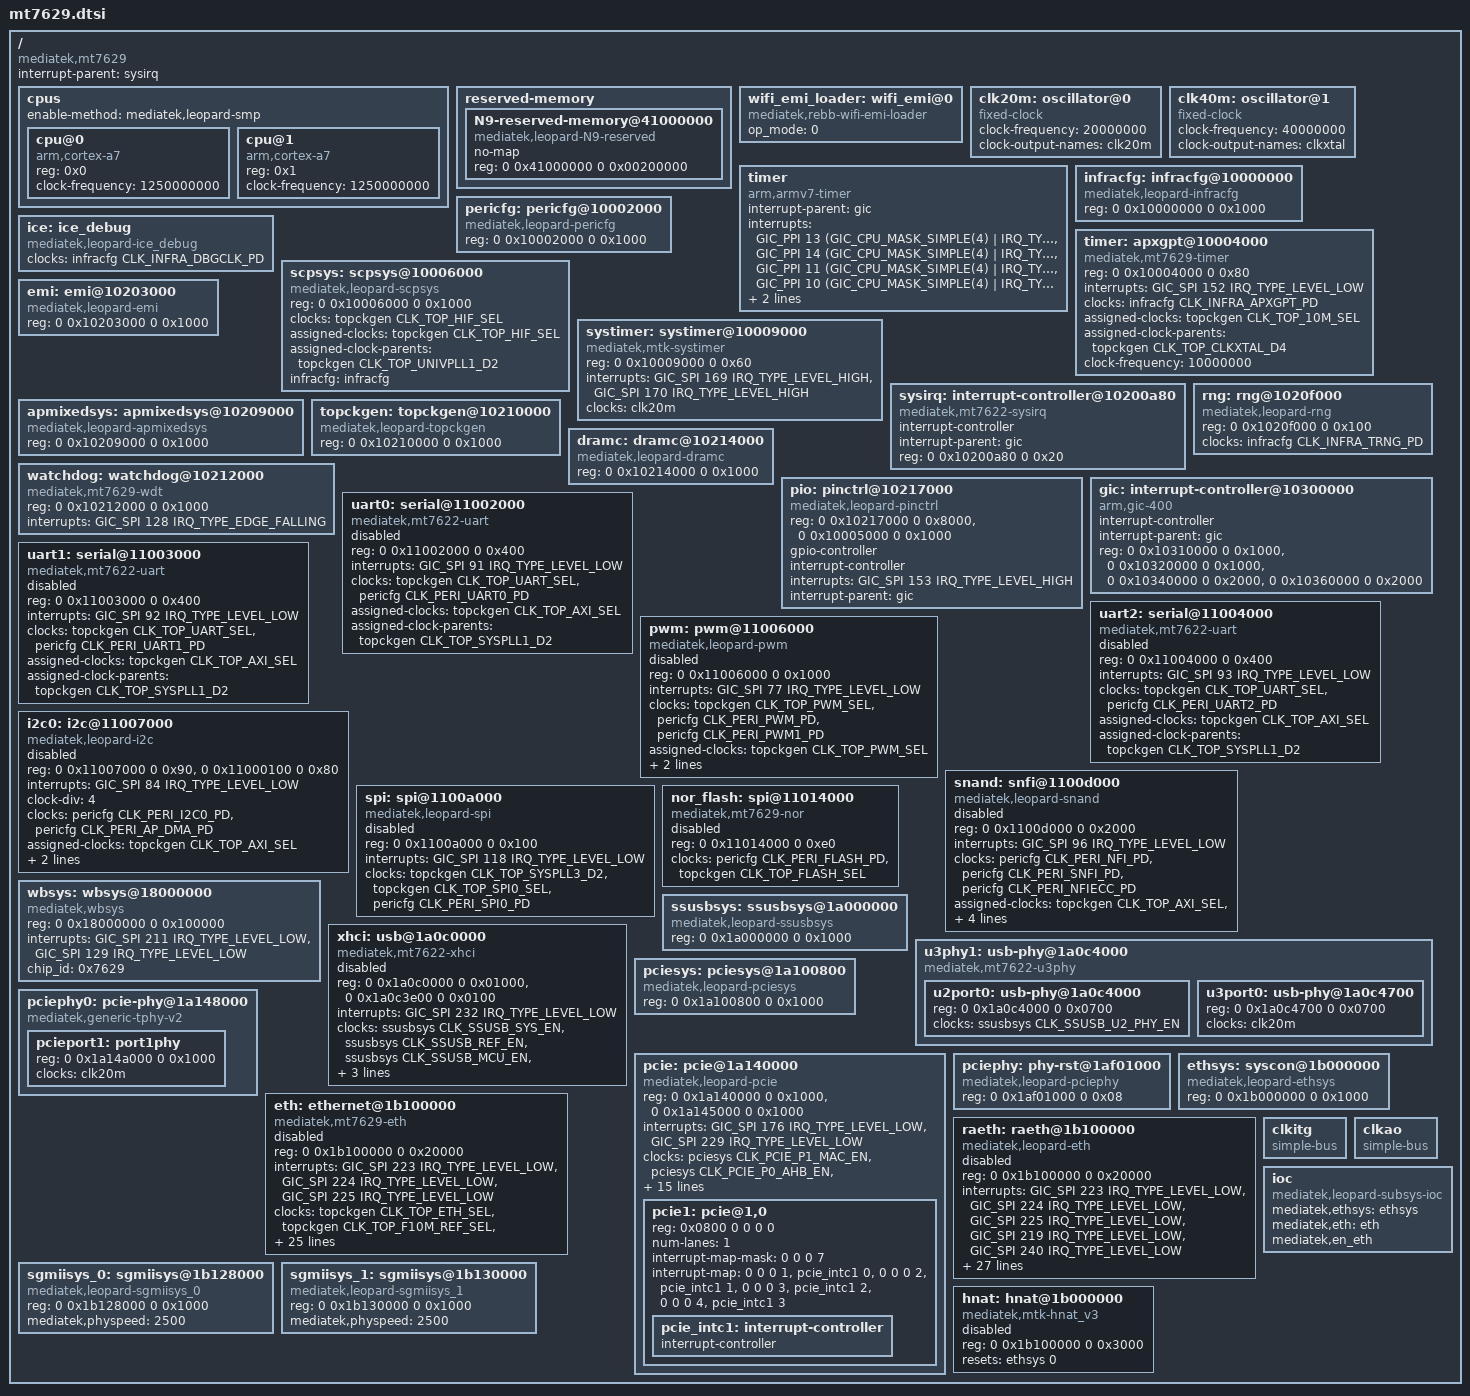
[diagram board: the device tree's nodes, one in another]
/*
 * Copyright (c) 2017 MediaTek Inc.
 * Author: Dehui.Sun <dehui.sun@mediatek.com>
 *
 * This program is free software; you can redistribute it and/or modify
 * it under the terms of the GNU General Public License version 2 as
 * published by the Free Software Foundation.
 *
 * This program is distributed in the hope that it will be useful,
 * but WITHOUT ANY WARRANTY; without even the implied warranty of
 * MERCHANTABILITY or FITNESS FOR A PARTICULAR PURPOSE.  See the
 * GNU General Public License for more details.
 */

#include <dt-bindings/clock/leopard-clk.h>
#include <dt-bindings/interrupt-controller/irq.h>
#include <dt-bindings/interrupt-controller/arm-gic.h>
#include <dt-bindings/power/mt7622-power.h>
#include <dt-bindings/reset-controller/leopard-resets.h>
#include <dt-bindings/phy/phy.h>
#include "skeleton64.dtsi"

/ {
	compatible = "mediatek,mt7629";
	interrupt-parent = <&sysirq>;
	#address-cells = <2>;
	#size-cells = <2>;

	cpus {
		#address-cells = <1>;
		#size-cells = <0>;
		enable-method = "mediatek,leopard-smp";

		cpu@0 {
			device_type = "cpu";
			compatible = "arm,cortex-a7";
			reg = <0x0>;
			clock-frequency = <1250000000>;
		};

		cpu@1 {
			device_type = "cpu";
			compatible = "arm,cortex-a7";
			reg = <0x1>;
			clock-frequency = <1250000000>;
		};
	};

	reserved-memory {
		#address-cells = <2>;
		#size-cells = <2>;
		ranges;

		N9-reserved-memory@41000000 {
			compatible = "mediatek,leopard-N9-reserved";
			no-map;
			reg = <0 0x41000000 0 0x00200000>;
		};
	};

	wifi_emi_loader: wifi_emi@0 {
		compatible = "mediatek,rebb-wifi-emi-loader";
		op_mode = <0>;
	};

	clk20m: oscillator@0 {
		compatible = "fixed-clock";
		#clock-cells = <0>;
		clock-frequency = <20000000>;
		clock-output-names = "clk20m";
	};

	clk40m: oscillator@1 {
		compatible = "fixed-clock";
		#clock-cells = <0>;
		clock-frequency = <40000000>;
		clock-output-names = "clkxtal";
	};

	timer {
		compatible = "arm,armv7-timer";
		interrupt-parent = <&gic>;
		interrupts = <GIC_PPI 13 (GIC_CPU_MASK_SIMPLE(4) | IRQ_TYPE_LEVEL_HIGH)>,
			     <GIC_PPI 14 (GIC_CPU_MASK_SIMPLE(4) | IRQ_TYPE_LEVEL_HIGH)>,
			     <GIC_PPI 11 (GIC_CPU_MASK_SIMPLE(4) | IRQ_TYPE_LEVEL_HIGH)>,
			     <GIC_PPI 10 (GIC_CPU_MASK_SIMPLE(4) | IRQ_TYPE_LEVEL_HIGH)>;
		clock-frequency = <20000000>;
		arm,cpu-registers-not-fw-configured;
	};

	infracfg: infracfg@10000000 {
		compatible = "mediatek,leopard-infracfg", "syscon";
		reg = <0 0x10000000 0 0x1000>;
		#clock-cells = <1>;
	};

	pericfg: pericfg@10002000 {
		compatible = "mediatek,leopard-pericfg", "syscon";
		reg = <0 0x10002000 0 0x1000>;
		#clock-cells = <1>;
	};

	ice: ice_debug {
		compatible ="mediatek,leopard-ice_debug",
			    "mediatek,mt2701-ice_debug";
		clocks = <&infracfg CLK_INFRA_DBGCLK_PD>;
		clock-names = "ice_dbg";
	};

	timer: apxgpt@10004000 {
		compatible = "mediatek,mt7629-timer",
			     "mediatek,mt6577-timer";
		reg = <0 0x10004000 0 0x80>;
		interrupts = <GIC_SPI 152 IRQ_TYPE_LEVEL_LOW>;
		clocks = <&infracfg CLK_INFRA_APXGPT_PD>;
		assigned-clocks = <&topckgen CLK_TOP_10M_SEL>;
		assigned-clock-parents = <&topckgen CLK_TOP_CLKXTAL_D4>;
		clock-names = "clk13m";
		clock-frequency = <10000000>;
	};

	scpsys: scpsys@10006000 {
		compatible = "mediatek,leopard-scpsys",
			     "mediatek,mt7622-scpsys";
		#power-domain-cells = <1>;
		reg = <0 0x10006000 0 0x1000>;
		clocks = <&topckgen CLK_TOP_HIF_SEL>;
		clock-names = "hif_sel";
		assigned-clocks = <&topckgen CLK_TOP_HIF_SEL>;
		assigned-clock-parents = <&topckgen CLK_TOP_UNIVPLL1_D2>;
		infracfg = <&infracfg>;
	};

	systimer: systimer@10009000 {
		compatible = "mediatek,mtk-systimer";
		reg = <0 0x10009000 0 0x60>;
		interrupts = <GIC_SPI 169 IRQ_TYPE_LEVEL_HIGH>,
			     <GIC_SPI 170 IRQ_TYPE_LEVEL_HIGH>;
		clocks = <&clk20m>;
		clock-names = "clk20m";
	};

	sysirq: interrupt-controller@10200a80 {
		compatible = "mediatek,mt7622-sysirq",
			     "mediatek,mt6577-sysirq";
		interrupt-controller;
		#interrupt-cells = <3>;
		interrupt-parent = <&gic>;
		reg = <0 0x10200a80 0 0x20>;
	};

	emi: emi@10203000 {
		compatible = "mediatek,leopard-emi",
			     "mediatek,mt8127-emi";
		reg = <0 0x10203000 0 0x1000>;
	};

	apmixedsys: apmixedsys@10209000 {
		compatible = "mediatek,leopard-apmixedsys", "syscon";
		reg = <0 0x10209000 0 0x1000>;
		#clock-cells = <1>;
	};

	rng: rng@1020f000 {
		compatible = "mediatek,leopard-rng",
			     "mediatek,mt7623-rng";
		reg = <0 0x1020f000 0 0x100>;
		clocks = <&infracfg CLK_INFRA_TRNG_PD>;
		clock-names = "rng";
	};

	topckgen: topckgen@10210000 {
		compatible = "mediatek,leopard-topckgen", "syscon";
		reg = <0 0x10210000 0 0x1000>;
		#clock-cells = <1>;
	};

	watchdog: watchdog@10212000 {
		compatible = "mediatek,mt7629-wdt",
			     "mediatek,mt6589-wdt";
		reg = <0 0x10212000 0 0x1000>;
		interrupts = <GIC_SPI 128 IRQ_TYPE_EDGE_FALLING>;
		#reset-cells = <1>;
	};

	dramc: dramc@10214000 {
		compatible = "mediatek,leopard-dramc";
		reg = <0 0x10214000 0 0x1000>;
	};

	pio: pinctrl@10217000 {
		compatible = "mediatek,leopard-pinctrl";
		reg = <0 0x10217000 0 0x8000>,
		      <0 0x10005000 0 0x1000>;
		reg-names = "base", "eint";
		gpio-controller;
		#gpio-cells = <2>;
		interrupt-controller;
		#interrupt-cells = <2>;
		interrupts = <GIC_SPI 153 IRQ_TYPE_LEVEL_HIGH>;
		interrupt-parent = <&gic>;
	};

	gic: interrupt-controller@10300000 {
		compatible = "arm,gic-400";
		interrupt-controller;
		#interrupt-cells = <3>;
		interrupt-parent = <&gic>;
		reg = <0 0x10310000 0 0x1000>,
		      <0 0x10320000 0 0x1000>,
		      <0 0x10340000 0 0x2000>,
		      <0 0x10360000 0 0x2000>;
	};

	uart0: serial@11002000 {
		compatible = "mediatek,mt7622-uart",
			     "mediatek,mt6577-uart";
		reg = <0 0x11002000 0 0x400>;
		interrupts = <GIC_SPI 91 IRQ_TYPE_LEVEL_LOW>;
		clocks = <&topckgen CLK_TOP_UART_SEL>,
			 <&pericfg CLK_PERI_UART0_PD>;
		clock-names = "baud", "bus";
		assigned-clocks = <&topckgen CLK_TOP_AXI_SEL>;
		assigned-clock-parents = <&topckgen CLK_TOP_SYSPLL1_D2>;
		status = "disabled";
	};

	uart1: serial@11003000 {
		compatible = "mediatek,mt7622-uart",
			     "mediatek,mt6577-uart";
		reg = <0 0x11003000 0 0x400>;
		interrupts = <GIC_SPI 92 IRQ_TYPE_LEVEL_LOW>;
		clocks = <&topckgen CLK_TOP_UART_SEL>,
			 <&pericfg CLK_PERI_UART1_PD>;
		clock-names = "baud", "bus";
		assigned-clocks = <&topckgen CLK_TOP_AXI_SEL>;
		assigned-clock-parents = <&topckgen CLK_TOP_SYSPLL1_D2>;
		status = "disabled";
	};

	uart2: serial@11004000 {
		compatible = "mediatek,mt7622-uart",
			     "mediatek,mt6577-uart";
		reg = <0 0x11004000 0 0x400>;
		interrupts = <GIC_SPI 93 IRQ_TYPE_LEVEL_LOW>;
		clocks = <&topckgen CLK_TOP_UART_SEL>,
			 <&pericfg CLK_PERI_UART2_PD>;
		clock-names = "baud", "bus";
		assigned-clocks = <&topckgen CLK_TOP_AXI_SEL>;
		assigned-clock-parents = <&topckgen CLK_TOP_SYSPLL1_D2>;
		status = "disabled";
	};

	pwm: pwm@11006000 {
		compatible = "mediatek,leopard-pwm";
		reg = <0 0x11006000 0 0x1000>;
		interrupts = <GIC_SPI 77 IRQ_TYPE_LEVEL_LOW>;
		clocks = <&topckgen CLK_TOP_PWM_SEL>,
			 <&pericfg CLK_PERI_PWM_PD>,
			 <&pericfg CLK_PERI_PWM1_PD>;
		clock-names = "top", "main", "pwm1";
		assigned-clocks = <&topckgen CLK_TOP_PWM_SEL>;
		assigned-clock-parents = <&topckgen CLK_TOP_UNIVPLL2_D4>;
		status = "disabled";
	};

	i2c0: i2c@11007000 {
		compatible = "mediatek,leopard-i2c";
		reg = <0 0x11007000 0 0x90>,
		      <0 0x11000100 0 0x80>;
		interrupts = <GIC_SPI 84 IRQ_TYPE_LEVEL_LOW>;
		clock-div = <4>;
		clocks = <&pericfg CLK_PERI_I2C0_PD>,
			 <&pericfg CLK_PERI_AP_DMA_PD>;
		clock-names = "main", "dma";
		assigned-clocks = <&topckgen CLK_TOP_AXI_SEL>;
		assigned-clock-parents = <&topckgen CLK_TOP_SYSPLL1_D2>;
		#address-cells = <1>;
		#size-cells = <0>;
		status = "disabled";
	};

	snand: snfi@1100d000 {
		compatible = "mediatek,leopard-snand";
		reg = <0 0x1100d000 0 0x2000>;
		interrupts = <GIC_SPI 96 IRQ_TYPE_LEVEL_LOW>;
		clocks = <&pericfg CLK_PERI_NFI_PD>,
			 <&pericfg CLK_PERI_SNFI_PD>,
			 <&pericfg CLK_PERI_NFIECC_PD>;
		clock-names = "nfi_clk", "pad_clk", "nfiecc_clk";
		assigned-clocks = <&topckgen CLK_TOP_AXI_SEL>,
				  <&topckgen CLK_TOP_NFI_INFRA_SEL>;
		assigned-clock-parents = <&topckgen CLK_TOP_SYSPLL1_D2>,
					 <&topckgen CLK_TOP_UNIVPLL2_D8>;
		#address-cells = <1>;
		#size-cells = <0>;
		status = "disabled";
	};

	spi: spi@1100a000 {
		compatible = "mediatek,leopard-spi";
		#address-cells = <1>;
		#size-cells = <0>;
		reg = <0 0x1100a000 0 0x100>;
		interrupts = <GIC_SPI 118 IRQ_TYPE_LEVEL_LOW>;
		clocks = <&topckgen CLK_TOP_SYSPLL3_D2>,
			 <&topckgen CLK_TOP_SPI0_SEL>,
			 <&pericfg CLK_PERI_SPI0_PD>;
		clock-names = "parent-clk", "sel-clk", "spi-clk";
		status = "disabled";
	};

	nor_flash: spi@11014000 {
		compatible = "mediatek,mt7629-nor",
			     "mediatek,mt8173-nor";
		reg = <0 0x11014000 0 0xe0>;
		clocks = <&pericfg CLK_PERI_FLASH_PD>,
			 <&topckgen CLK_TOP_FLASH_SEL>;
		clock-names = "spi", "sf";
		#address-cells = <1>;
		#size-cells = <0>;
		status = "disabled";
	};

	wbsys: wbsys@18000000 {
		compatible = "mediatek,wbsys";
		reg = <0 0x18000000 0  0x100000>;
		interrupts = <GIC_SPI 211 IRQ_TYPE_LEVEL_LOW>,
			     <GIC_SPI 129 IRQ_TYPE_LEVEL_LOW>;
		chip_id = <0x7629>;
	};

	ssusbsys: ssusbsys@1a000000 {
		compatible = "mediatek,leopard-ssusbsys", "syscon";
		reg = <0 0x1a000000 0 0x1000>;
		#clock-cells = <1>;
		#reset-cells = <1>;
	};

	xhci: usb@1a0c0000 {
		compatible = "mediatek,mt7622-xhci", "mediatek,mt2701-xhci";
		reg = <0 0x1a0c0000 0 0x01000>,
		      <0 0x1a0c3e00 0 0x0100>;
		reg-names = "mac", "ippc";
		interrupts = <GIC_SPI 232 IRQ_TYPE_LEVEL_LOW>;
		//power-domains = <&scpsys MT7622_POWER_DOMAIN_HIF1>;
		clocks = <&ssusbsys CLK_SSUSB_SYS_EN>, <&ssusbsys CLK_SSUSB_REF_EN>,
			 <&ssusbsys CLK_SSUSB_MCU_EN>, <&ssusbsys CLK_SSUSB_DMA_EN>;
		clock-names = "sys_ck", "free_ck", "ahb_ck", "dma_ck";
		phys = <&u2port0 PHY_TYPE_USB2>,
		<&u3port0 PHY_TYPE_USB3>;
		status = "disabled";
	};

	u3phy1: usb-phy@1a0c4000 {
		compatible = "mediatek,mt7622-u3phy", "mediatek,mt2712-u3phy";
		#address-cells = <2>;
		#size-cells = <2>;
		ranges;
		status = "okay";

		u2port0: usb-phy@1a0c4000 {
			reg = <0 0x1a0c4000 0 0x0700>;
			#phy-cells = <1>;
			clocks = <&ssusbsys CLK_SSUSB_U2_PHY_EN>;
			clock-names = "ref";
		};

		u3port0: usb-phy@1a0c4700 {
			reg = <0 0x1a0c4700 0 0x0700>;
			#phy-cells = <1>;
			clocks = <&clk20m>;
			clock-names = "ref";
		};
	};

	pciesys: pciesys@1a100800 {
		compatible = "mediatek,leopard-pciesys", "syscon";
		reg = <0 0x1a100800 0 0x1000>;
		#clock-cells = <1>;
		#reset-cells = <1>;
	};

	pcie: pcie@1a140000 {
		compatible = "mediatek,leopard-pcie";
		device_type = "pci";
		reg = <0 0x1a140000 0 0x1000>,
		      <0 0x1a145000 0 0x1000>;
		reg-names = "subsys","port1";
		#address-cells = <3>;
		#size-cells = <2>;
		interrupts = <GIC_SPI 176 IRQ_TYPE_LEVEL_LOW>,
			     <GIC_SPI 229 IRQ_TYPE_LEVEL_LOW>;
		clocks = <&pciesys CLK_PCIE_P1_MAC_EN>,
			 <&pciesys CLK_PCIE_P0_AHB_EN>,
			 <&pciesys CLK_PCIE_P1_AUX_EN>,
			 <&pciesys CLK_PCIE_P1_AXI_EN>,
			 <&pciesys CLK_PCIE_P1_OBFF_EN>,
			 <&pciesys CLK_PCIE_P1_PIPE_EN>;
		clock-names = "sys_ck1", "ahb_ck1",
			      "aux_ck1", "axi_ck1",
			      "obff_ck1", "pipe_ck1";
		assigned-clocks = <&topckgen CLK_TOP_SATA_SEL>,
				  <&topckgen CLK_TOP_AXI_SEL>,
				  <&topckgen CLK_TOP_HIF_SEL>;
		assigned-clock-parents = <&topckgen CLK_TOP_UNIVPLL2_D4>,
					 <&topckgen CLK_TOP_SYSPLL1_D2>,
					 <&topckgen CLK_TOP_UNIVPLL1_D2>;
		resets = <&pciephy LEOPARD_PCIE1_PHY_RST>;
		reset-names = "phy-rst1";
		phys = <&pcieport1 PHY_TYPE_PCIE>;
		phy-names = "pcie-phy1";
		power-domains = <&scpsys MT7622_POWER_DOMAIN_HIF0>;
		bus-range = <0x00 0xff>;
		ranges = <0x82000000 0 0x20000000  0x0 0x20000000  0 0x10000000>;

		pcie1: pcie@1,0 {
			device_type = "pci";
			reg = <0x0800 0 0 0 0>;
			#address-cells = <3>;
			#size-cells = <2>;
			#interrupt-cells = <1>;
			ranges;
			num-lanes = <1>;
			interrupt-map-mask = <0 0 0 7>;
			interrupt-map = <0 0 0 1 &pcie_intc1 0>,
					<0 0 0 2 &pcie_intc1 1>,
					<0 0 0 3 &pcie_intc1 2>,
					<0 0 0 4 &pcie_intc1 3>;
			pcie_intc1: interrupt-controller {
				interrupt-controller;
				#address-cells = <0>;
				#interrupt-cells = <1>;
			};
		};
	};

	pciephy0: pcie-phy@1a148000 {
		compatible = "mediatek,generic-tphy-v2";
		#address-cells = <2>;
		#size-cells = <2>;
		ranges;

		pcieport1: port1phy {
			reg = <0 0x1a14a000 0 0x1000>;
			clocks = <&clk20m>;
			clock-names = "ref";
			#phy-cells = <1>;
		};
	};

	pciephy: phy-rst@1af01000 {
		compatible = "mediatek,leopard-pciephy", "syscon";
		reg = <0 0x1af01000 0 0x08>;
		#reset-cells = <1>;
	};

	ethsys: syscon@1b000000 {
		#address-cells = <1>;
		#size-cells = <1>;
		compatible = "mediatek,leopard-ethsys",
			     "syscon";
		reg = <0 0x1b000000 0 0x1000>;
		#clock-cells = <1>;
		#reset-cells = <1>;
	};


	eth: ethernet@1b100000 {
		compatible = "mediatek,mt7629-eth",
				"syscon";
		reg = <0 0x1b100000 0 0x20000>;
		interrupts = <GIC_SPI 223 IRQ_TYPE_LEVEL_LOW>,
			     <GIC_SPI 224 IRQ_TYPE_LEVEL_LOW>,
			     <GIC_SPI 225 IRQ_TYPE_LEVEL_LOW>;
		clocks = <&topckgen CLK_TOP_ETH_SEL>,
			 <&topckgen CLK_TOP_F10M_REF_SEL>,
			 <&ethsys CLK_ETH_ESW_EN>,
			 <&ethsys CLK_ETH_GP0_EN>,
			 <&ethsys CLK_ETH_GP1_EN>,
			 <&ethsys CLK_ETH_GP2_EN>,
			 <&ethsys CLK_ETH_FE_EN>,
			 <&sgmiisys_0 CLK_SGMII0_TX_EN>,
			 <&sgmiisys_0 CLK_SGMII0_RX_EN>,
			 <&sgmiisys_0 CLK_SGMII0_CDR_REF>,
			 <&sgmiisys_0 CLK_SGMII0_CDR_FB>,
			 <&sgmiisys_1 CLK_SGMII1_TX_EN>,
			 <&sgmiisys_1 CLK_SGMII1_RX_EN>,
			 <&sgmiisys_1 CLK_SGMII1_CDR_REF>,
			 <&sgmiisys_1 CLK_SGMII1_CDR_FB>,
			 <&apmixedsys CLK_APMIXED_SGMIPLL>,
			 <&apmixedsys CLK_APMIXED_ETH2PLL>;
		clock-names = "ethif", "sgmiitop", "esw", "gp0", "gp1", "gp2",
			      "fe", "sgmii_tx250m", "sgmii_rx250m",
			      "sgmii_cdr_ref", "sgmii_cdr_fb",
			      "sgmii2_tx250m", "sgmii2_rx250m",
			      "sgmii2_cdr_ref", "sgmii2_cdr_fb",
			      "sgmii_ck", "eth2pll";
		assigned-clocks = <&topckgen CLK_TOP_ETH_SEL>,
				  <&topckgen CLK_TOP_F10M_REF_SEL>;
		assigned-clock-parents = <&topckgen CLK_TOP_UNIVPLL1_D2>,
					 <&topckgen CLK_TOP_SGMIIPLL_D2>;
		power-domains = <&scpsys MT7622_POWER_DOMAIN_ETHSYS>;
		mediatek,ethsys = <&ethsys>;
		mediatek,sgmiisys = <&sgmiisys_0>,<&sgmiisys_1>;
		mediatek,infracfg = <&infracfg>;
		dma-coherent;
		#address-cells = <1>;
		#size-cells = <0>;
		status = "disabled";
	};

	raeth: raeth@1b100000 {
		compatible = "mediatek,leopard-eth";
		reg = <0 0x1b100000 0 0x20000>;
		interrupts = <GIC_SPI 223 IRQ_TYPE_LEVEL_LOW>,
			     <GIC_SPI 224 IRQ_TYPE_LEVEL_LOW>,
			     <GIC_SPI 225 IRQ_TYPE_LEVEL_LOW>,
			     <GIC_SPI 219 IRQ_TYPE_LEVEL_LOW>,
			     <GIC_SPI 240 IRQ_TYPE_LEVEL_LOW>;
		clocks = <&topckgen CLK_TOP_ETH_SEL>,
			 <&topckgen CLK_TOP_F10M_REF_SEL>,
			 <&topckgen CLK_TOP_SGMII_REF_1_SEL>,
			 <&apmixedsys CLK_APMIXED_ETH1PLL>,
			 <&apmixedsys CLK_APMIXED_ETH2PLL>,
			 <&apmixedsys CLK_APMIXED_SGMIPLL>,
			 <&ethsys CLK_ETH_FE_EN>,
			 <&ethsys CLK_ETH_ESW_EN>,
			 <&ethsys CLK_ETH_GP2_EN>,
			 <&ethsys CLK_ETH_GP1_EN>,
			 <&ethsys CLK_ETH_GP0_EN>,
			 <&sgmiisys_0 CLK_SGMII0_TX_EN>,
			 <&sgmiisys_0 CLK_SGMII0_RX_EN>,
			 <&sgmiisys_0 CLK_SGMII0_CDR_REF>,
			 <&sgmiisys_0 CLK_SGMII0_CDR_FB>,
			 <&sgmiisys_1 CLK_SGMII1_TX_EN>,
			 <&sgmiisys_1 CLK_SGMII1_RX_EN>,
			 <&sgmiisys_1 CLK_SGMII1_CDR_REF>,
			 <&sgmiisys_1 CLK_SGMII1_CDR_FB>;
		clock-names = "ethif", "sgmiitop", "sgmii1top",
			      "eth1pll", "eth2pll",
			      "sgmipll", "eth", "esw", "gp2",
			      "gp1", "gp0", "sgmii_tx250m",
			      "sgmii_rx250m", "sgmii_cdr_ref",
			      "sgmii_cdr_fb", "sgmii1_tx250m",
			      "sgmii1_rx250m", "sgmii1_cdr_ref",
			      "sgmii1_cdr_fb";
		assigned-clocks = <&topckgen CLK_TOP_ETH_SEL>,
				  <&topckgen CLK_TOP_F10M_REF_SEL>;
		assigned-clock-parents = <&topckgen CLK_TOP_UNIVPLL1_D2>,
					 <&topckgen CLK_TOP_SGMIIPLL_D2>;
		power-domains = <&scpsys MT7622_POWER_DOMAIN_ETHSYS>;
		mediatek,ethsys = <&ethsys>;
		dma-coherent;
		#reset-cells = <1>;
		#address-cells = <1>;
		#size-cells = <0>;
		status = "disabled";
	};

	sgmiisys_0: sgmiisys@1b128000 {
		compatible = "mediatek,leopard-sgmiisys_0", "syscon";
		reg = <0 0x1b128000 0 0x1000>;
		#clock-cells = <1>;
		mediatek,physpeed = "2500";
	};

	sgmiisys_1: sgmiisys@1b130000 {
		compatible = "mediatek,leopard-sgmiisys_1", "syscon";
		reg = <0 0x1b130000 0 0x1000>;
		#clock-cells = <1>;
		mediatek,physpeed = "2500";
	};

	hnat: hnat@1b000000 {
		compatible = "mediatek,mtk-hnat_v3";
		reg = <0 0x1b100000 0 0x3000>;
		resets = <&ethsys 0>;
		reset-names = "mtketh";
		status = "disabled";
	};

	clkitg: clkitg {
		compatible = "simple-bus";
	};

	clkao: clkao {
		compatible = "simple-bus";
	};

	ioc {
		compatible = "mediatek,leopard-subsys-ioc";
		mediatek,ethsys = <&ethsys>;
		mediatek,eth = <&eth>;
		mediatek,en_eth;
	};
};

#include "leopard-clkitg.dtsi"
#include "leopard-clkao.dtsi"

